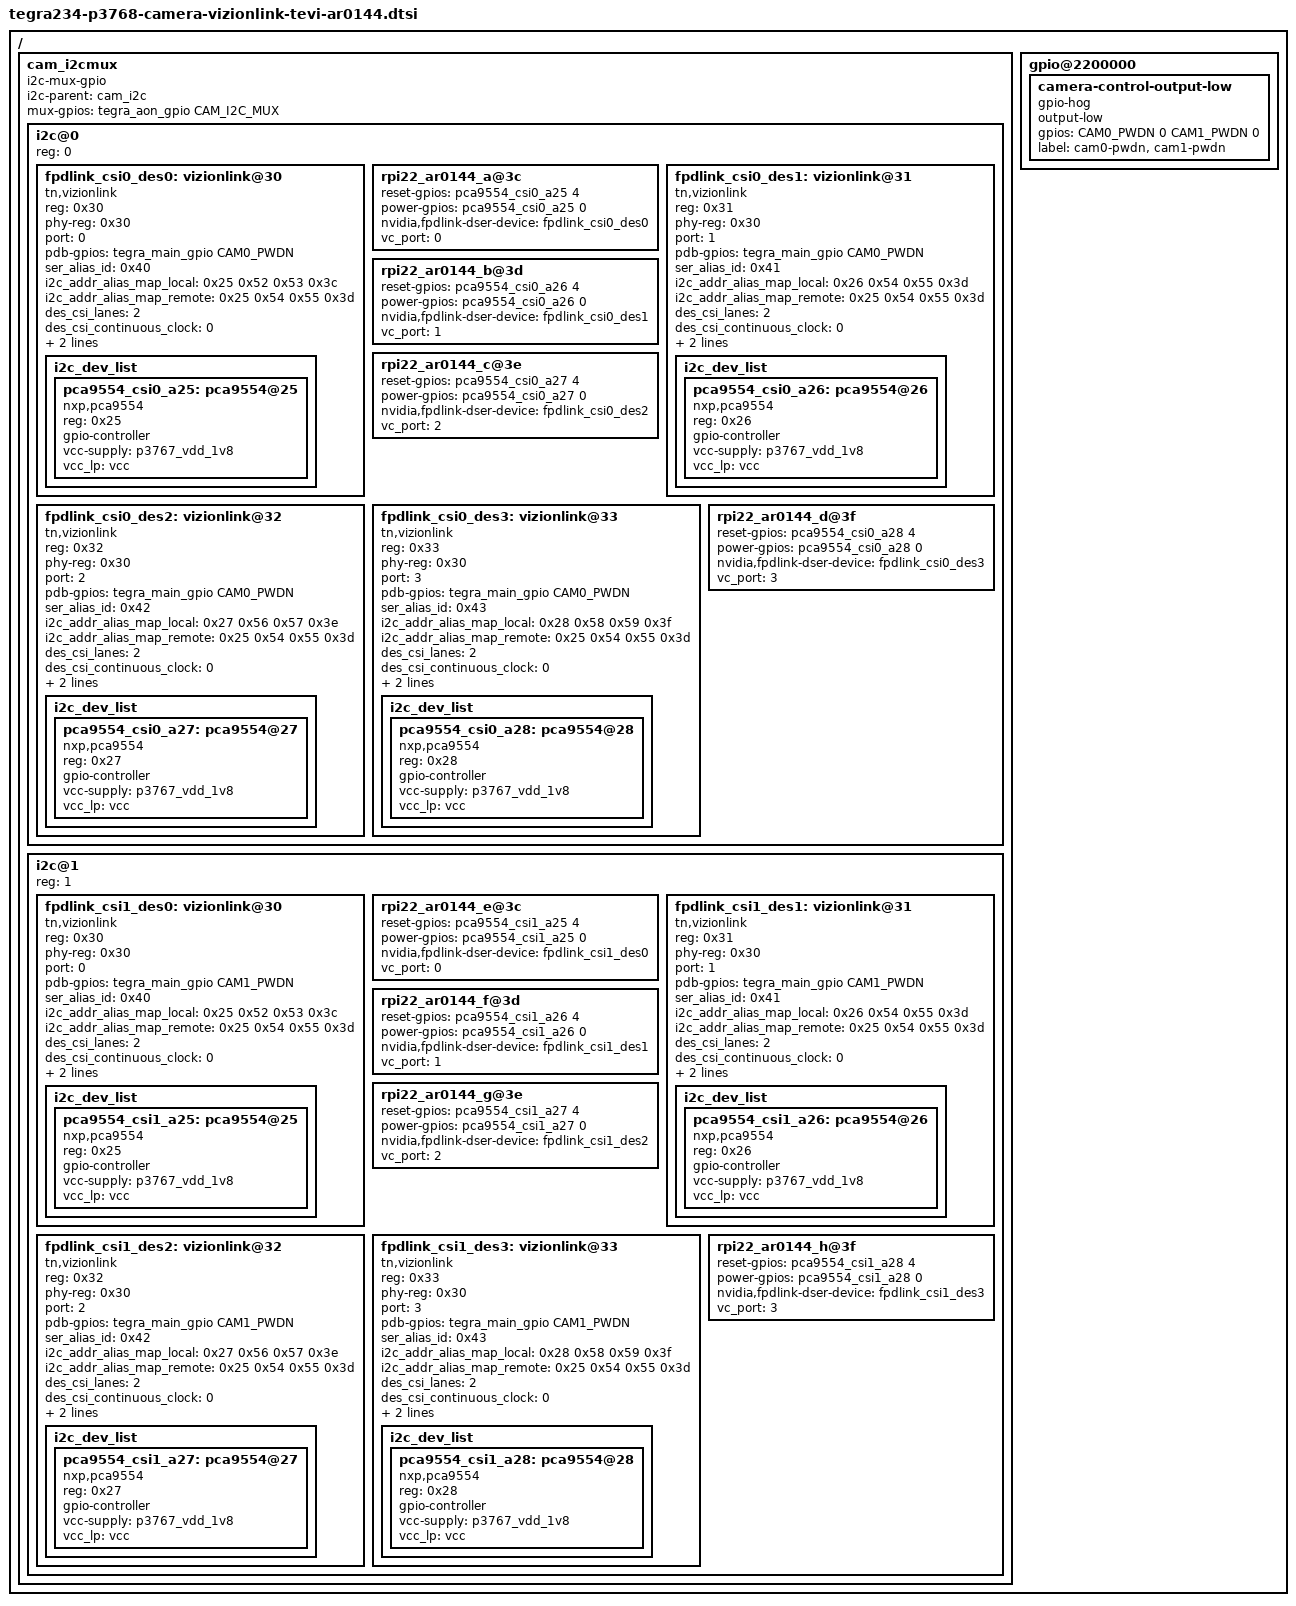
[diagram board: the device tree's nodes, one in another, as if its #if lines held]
/*
 * Copyright (c) 2022, NVIDIA CORPORATION.  All rights reserved.
 *
 * This program is free software; you can redistribute it and/or modify
 * it under the terms of the GNU General Public License as published by
 * the Free Software Foundation; either version 2 of the License, or
 * (at your option) any later version.
 *
 * This program is distributed in the hope that it will be useful, but WITHOUT
 * ANY WARRANTY; without even the implied warranty of MERCHANTABILITY or
 * FITNESS FOR A PARTICULAR PURPOSE.  See the GNU General Public License for
 * more details.
 *
 * You should have received a copy of the GNU General Public License
 * along with this program.  If not, see <http://www.gnu.org/licenses/>.
 */

#include "tegra234-camera-vls316-tevi-ar0144.dtsi"

#define CAM0_PWDN	TEGRA234_MAIN_GPIO(H, 6)
#define CAM1_PWDN	TEGRA234_MAIN_GPIO(AC, 0)
#define CAM_I2C_MUX 	TEGRA234_AON_GPIO(CC, 3)

/ {
	cam_i2cmux{
		status = "okay";
		compatible = "i2c-mux-gpio";
		#address-cells = <1>;
		#size-cells = <0>;
		i2c-parent = <&cam_i2c>;
		mux-gpios = <&tegra_aon_gpio CAM_I2C_MUX GPIO_ACTIVE_HIGH>;
		i2c@0 {
			status = "okay";
			reg = <0>;
			#address-cells = <1>;
			#size-cells = <0>;
#ifdef VLI_TEVI_AR0144_CSI0_CAM0
			fpdlink_csi0_des0: vizionlink@30 {
				compatible = "tn,vizionlink";
				reg = <0x30>;
				phy-reg = <0x30>;
				port = <0>;
				pdb-gpios = <&tegra_main_gpio CAM0_PWDN GPIO_ACTIVE_HIGH>;
				ser_alias_id = <0x40>;

				//i2c addr alias map "gpio extender, eeprom addr1, eeprom addr2, sensor"
				i2c_addr_alias_map_local = <0x25 0x52 0x53 0x3c>;
				i2c_addr_alias_map_remote = <0x25 0x54 0x55 0x3d>;

				//deserializer output csi lanes 1~4. default 4
				des_csi_lanes = <2>;

				//1: Enable 0: Disable continuous clock. default 0
				des_csi_continuous_clock = <0>;

				//serializer input csi lanes 1~4. default 4
				ser_csi_lanes = <2>;

				//1: Enable 0: Disable continuous clock. default 0
				ser_csi_continuous_clock = <0>;

				status = "okay";

				i2c_dev_list {
					#address-cells = <1>;
					#size-cells = <0>;

					pca9554_csi0_a25: pca9554@25 {
						compatible = "nxp,pca9554";
						reg = <0x25>;
						gpio-controller;
						#gpio-cells = <2>;
						vcc-supply = <&p3767_vdd_1v8>;
						vcc_lp = "vcc";
						status = "okay";
					};
				};
			};
			rpi22_ar0144_a@3c {
				reset-gpios = <&pca9554_csi0_a25 4 GPIO_ACTIVE_HIGH>;
				power-gpios = <&pca9554_csi0_a25 0 GPIO_ACTIVE_HIGH>;

				nvidia,fpdlink-dser-device = <&fpdlink_csi0_des0>;
				vc_port = <0>;
				// status = "disabled";
			};
#endif
#ifdef VLI_TEVI_AR0144_CSI0_CAM1
			fpdlink_csi0_des1: vizionlink@31 {
				compatible = "tn,vizionlink";
				reg = <0x31>;
				phy-reg = <0x30>;
				port = <1>;
				pdb-gpios = <&tegra_main_gpio CAM0_PWDN GPIO_ACTIVE_HIGH>;
				ser_alias_id = <0x41>;

				//i2c addr alias map "gpio extender, eeprom addr1, eeprom addr2, sensor"
				i2c_addr_alias_map_local = <0x26 0x54 0x55 0x3d>;
				i2c_addr_alias_map_remote = <0x25 0x54 0x55 0x3d>;

				//deserializer output csi lanes 1~4. default 4
				des_csi_lanes = <2>;

				//1: Enable 0: Disable continuous clock. default 0
				des_csi_continuous_clock = <0>;

				//serializer input csi lanes 1~4. default 4
				ser_csi_lanes = <2>;

				//1: Enable 0: Disable continuous clock. default 0
				ser_csi_continuous_clock = <0>;

				status = "okay";

				i2c_dev_list {
					#address-cells = <1>;
					#size-cells = <0>;

					pca9554_csi0_a26: pca9554@26 {
						compatible = "nxp,pca9554";
						reg = <0x26>;
						gpio-controller;
						#gpio-cells = <2>;
						vcc-supply = <&p3767_vdd_1v8>;
						vcc_lp = "vcc";
						status = "okay";
					};
				};
			};
			rpi22_ar0144_b@3d {
				reset-gpios = <&pca9554_csi0_a26 4 GPIO_ACTIVE_HIGH>;
				power-gpios = <&pca9554_csi0_a26 0 GPIO_ACTIVE_HIGH>;

				nvidia,fpdlink-dser-device = <&fpdlink_csi0_des1>;
				vc_port = <1>;
			};
#endif
#ifdef VLI_TEVI_AR0144_CSI0_CAM2
			fpdlink_csi0_des2: vizionlink@32 {
				compatible = "tn,vizionlink";
				reg = <0x32>;
				phy-reg = <0x30>;
				port = <2>;
				pdb-gpios = <&tegra_main_gpio CAM0_PWDN GPIO_ACTIVE_HIGH>;
				ser_alias_id = <0x42>;

				//i2c addr alias map "gpio extender, eeprom addr1, eeprom addr2, sensor"
				i2c_addr_alias_map_local = <0x27 0x56 0x57 0x3e>;
				i2c_addr_alias_map_remote = <0x25 0x54 0x55 0x3d>;

				//deserializer output csi lanes 1~4. default 4
				des_csi_lanes = <2>;

				//1: Enable 0: Disable continuous clock. default 0
				des_csi_continuous_clock = <0>;

				//serializer input csi lanes 1~4. default 4
				ser_csi_lanes = <2>;

				//1: Enable 0: Disable continuous clock. default 0
				ser_csi_continuous_clock = <0>;

				status = "okay";

				i2c_dev_list {
					#address-cells = <1>;
					#size-cells = <0>;

					pca9554_csi0_a27: pca9554@27 {
						compatible = "nxp,pca9554";
						reg = <0x27>;
						gpio-controller;
						#gpio-cells = <2>;
						vcc-supply = <&p3767_vdd_1v8>;
						vcc_lp = "vcc";
						status = "okay";
					};
				};
			};
			rpi22_ar0144_c@3e {
				reset-gpios = <&pca9554_csi0_a27 4 GPIO_ACTIVE_HIGH>;
				power-gpios = <&pca9554_csi0_a27 0 GPIO_ACTIVE_HIGH>;

				nvidia,fpdlink-dser-device = <&fpdlink_csi0_des2>;
				vc_port = <2>;
			};
#endif
#ifdef VLI_TEVI_AR0144_CSI0_CAM3
			fpdlink_csi0_des3: vizionlink@33 {
				compatible = "tn,vizionlink";
				reg = <0x33>;
				phy-reg = <0x30>;
				port = <3>;
				pdb-gpios = <&tegra_main_gpio CAM0_PWDN GPIO_ACTIVE_HIGH>;
				ser_alias_id = <0x43>;

				//i2c addr alias map "gpio extender, eeprom addr1, eeprom addr2, sensor"
				i2c_addr_alias_map_local = <0x28 0x58 0x59 0x3f>;
				i2c_addr_alias_map_remote = <0x25 0x54 0x55 0x3d>;

				//deserializer output csi lanes 1~4. default 4
				des_csi_lanes = <2>;

				//1: Enable 0: Disable continuous clock. default 0
				des_csi_continuous_clock = <0>;

				//serializer input csi lanes 1~4. default 4
				ser_csi_lanes = <2>;

				//1: Enable 0: Disable continuous clock. default 0
				ser_csi_continuous_clock = <0>;

				status = "okay";

				i2c_dev_list {
					#address-cells = <1>;
					#size-cells = <0>;

					pca9554_csi0_a28: pca9554@28 {
						compatible = "nxp,pca9554";
						reg = <0x28>;
						gpio-controller;
						#gpio-cells = <2>;
						vcc-supply = <&p3767_vdd_1v8>;
						vcc_lp = "vcc";
						status = "okay";
					};
				};
			};
			rpi22_ar0144_d@3f {
				reset-gpios = <&pca9554_csi0_a28 4 GPIO_ACTIVE_HIGH>;
				power-gpios = <&pca9554_csi0_a28 0 GPIO_ACTIVE_HIGH>;

				nvidia,fpdlink-dser-device = <&fpdlink_csi0_des3>;
				vc_port = <3>;
			};
#endif
		};
		i2c@1 {
			status = "okay";
			reg = <1>;
			#address-cells = <1>;
			#size-cells = <0>;
#ifdef VLI_TEVI_AR0144_CSI1_CAM0
			fpdlink_csi1_des0: vizionlink@30 {
				compatible = "tn,vizionlink";
				reg = <0x30>;
				phy-reg = <0x30>;
				port = <0>;
				pdb-gpios = <&tegra_main_gpio CAM1_PWDN GPIO_ACTIVE_HIGH>;
				ser_alias_id = <0x40>;

				//i2c addr alias map "gpio extender, eeprom addr1, eeprom addr2, sensor"
				i2c_addr_alias_map_local = <0x25 0x52 0x53 0x3c>;
				i2c_addr_alias_map_remote = <0x25 0x54 0x55 0x3d>;

				//deserializer output csi lanes 1~4. default 4
				des_csi_lanes = <2>;

				//1: Enable 0: Disable continuous clock. default 0
				des_csi_continuous_clock = <0>;

				//serializer input csi lanes 1~4. default 4
				ser_csi_lanes = <2>;

				//1: Enable 0: Disable continuous clock. default 0
				ser_csi_continuous_clock = <0>;

				status = "okay";

				i2c_dev_list {
					#address-cells = <1>;
					#size-cells = <0>;

					pca9554_csi1_a25: pca9554@25 {
						compatible = "nxp,pca9554";
						reg = <0x25>;
						gpio-controller;
						#gpio-cells = <2>;
						vcc-supply = <&p3767_vdd_1v8>;
						vcc_lp = "vcc";
						status = "okay";
					};
				};
			};

			rpi22_ar0144_e@3c {
				reset-gpios = <&pca9554_csi1_a25 4 GPIO_ACTIVE_HIGH>;
				power-gpios = <&pca9554_csi1_a25 0 GPIO_ACTIVE_HIGH>;

				nvidia,fpdlink-dser-device = <&fpdlink_csi1_des0>;
				vc_port = <0>;
			};
#endif
#ifdef VLI_TEVI_AR0144_CSI1_CAM1
			fpdlink_csi1_des1: vizionlink@31 {
				compatible = "tn,vizionlink";
				reg = <0x31>;
				phy-reg = <0x30>;
				port = <1>;
				pdb-gpios = <&tegra_main_gpio CAM1_PWDN GPIO_ACTIVE_HIGH>;
				ser_alias_id = <0x41>;

				//i2c addr alias map "gpio extender, eeprom addr1, eeprom addr2, sensor"
				i2c_addr_alias_map_local = <0x26 0x54 0x55 0x3d>;
				i2c_addr_alias_map_remote = <0x25 0x54 0x55 0x3d>;

				//deserializer output csi lanes 1~4. default 4
				des_csi_lanes = <2>;

				//1: Enable 0: Disable continuous clock. default 0
				des_csi_continuous_clock = <0>;

				//serializer input csi lanes 1~4. default 4
				ser_csi_lanes = <2>;

				//1: Enable 0: Disable continuous clock. default 0
				ser_csi_continuous_clock = <0>;

				status = "okay";

				i2c_dev_list {
					#address-cells = <1>;
					#size-cells = <0>;

					pca9554_csi1_a26: pca9554@26 {
						compatible = "nxp,pca9554";
						reg = <0x26>;
						gpio-controller;
						#gpio-cells = <2>;
						vcc-supply = <&p3767_vdd_1v8>;
						vcc_lp = "vcc";
						status = "okay";
					};
				};
			};

			rpi22_ar0144_f@3d {
				reset-gpios = <&pca9554_csi1_a26 4 GPIO_ACTIVE_HIGH>;
				power-gpios = <&pca9554_csi1_a26 0 GPIO_ACTIVE_HIGH>;

				nvidia,fpdlink-dser-device = <&fpdlink_csi1_des1>;
				vc_port = <1>;
			};
#endif
#ifdef VLI_TEVI_AR0144_CSI1_CAM2
			fpdlink_csi1_des2: vizionlink@32 {
				compatible = "tn,vizionlink";
				reg = <0x32>;
				phy-reg = <0x30>;
				port = <2>;
				pdb-gpios = <&tegra_main_gpio CAM1_PWDN GPIO_ACTIVE_HIGH>;
				ser_alias_id = <0x42>;

				//i2c addr alias map "gpio extender, eeprom addr1, eeprom addr2, sensor"
				i2c_addr_alias_map_local = <0x27 0x56 0x57 0x3e>;
				i2c_addr_alias_map_remote = <0x25 0x54 0x55 0x3d>;

				//deserializer output csi lanes 1~4. default 4
				des_csi_lanes = <2>;

				//1: Enable 0: Disable continuous clock. default 0
				des_csi_continuous_clock = <0>;

				//serializer input csi lanes 1~4. default 4
				ser_csi_lanes = <2>;

				//1: Enable 0: Disable continuous clock. default 0
				ser_csi_continuous_clock = <0>;

				status = "okay";

				i2c_dev_list {
					#address-cells = <1>;
					#size-cells = <0>;

					pca9554_csi1_a27: pca9554@27 {
						compatible = "nxp,pca9554";
						reg = <0x27>;
						gpio-controller;
						#gpio-cells = <2>;
						vcc-supply = <&p3767_vdd_1v8>;
						vcc_lp = "vcc";
						status = "okay";
					};
				};
			};

			rpi22_ar0144_g@3e {
				reset-gpios = <&pca9554_csi1_a27 4 GPIO_ACTIVE_HIGH>;
				power-gpios = <&pca9554_csi1_a27 0 GPIO_ACTIVE_HIGH>;

				nvidia,fpdlink-dser-device = <&fpdlink_csi1_des2>;
				vc_port = <2>;
			};
#endif
#ifdef VLI_TEVI_AR0144_CSI1_CAM3
			fpdlink_csi1_des3: vizionlink@33 {
				compatible = "tn,vizionlink";
				reg = <0x33>;
				phy-reg = <0x30>;
				port = <3>;
				pdb-gpios = <&tegra_main_gpio CAM1_PWDN GPIO_ACTIVE_HIGH>;
				ser_alias_id = <0x43>;

				//i2c addr alias map "gpio extender, eeprom addr1, eeprom addr2, sensor"
				i2c_addr_alias_map_local = <0x28 0x58 0x59 0x3f>;
				i2c_addr_alias_map_remote = <0x25 0x54 0x55 0x3d>;

				//deserializer output csi lanes 1~4. default 4
				des_csi_lanes = <2>;

				//1: Enable 0: Disable continuous clock. default 0
				des_csi_continuous_clock = <0>;

				//serializer input csi lanes 1~4. default 4
				ser_csi_lanes = <2>;

				//1: Enable 0: Disable continuous clock. default 0
				ser_csi_continuous_clock = <0>;

				status = "okay";

				i2c_dev_list {
					#address-cells = <1>;
					#size-cells = <0>;

					pca9554_csi1_a28: pca9554@28 {
						compatible = "nxp,pca9554";
						reg = <0x28>;
						gpio-controller;
						#gpio-cells = <2>;
						vcc-supply = <&p3767_vdd_1v8>;
						vcc_lp = "vcc";
						status = "okay";
					};
				};
			};

			rpi22_ar0144_h@3f {
				reset-gpios = <&pca9554_csi1_a28 4 GPIO_ACTIVE_HIGH>;
				power-gpios = <&pca9554_csi1_a28 0 GPIO_ACTIVE_HIGH>;

				nvidia,fpdlink-dser-device = <&fpdlink_csi1_des3>;
				vc_port = <3>;
			};
#endif
		};
	};

	gpio@2200000 {
		camera-control-output-low {
			gpio-hog;
			output-low;
			gpios = <CAM0_PWDN 0 CAM1_PWDN 0>;
			label = "cam0-pwdn","cam1-pwdn";
		};
	};
};
